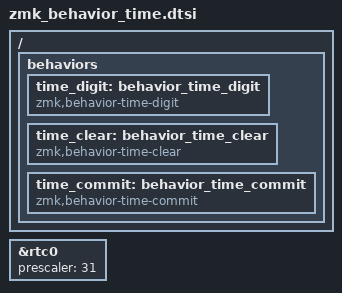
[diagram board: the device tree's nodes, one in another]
/*
 * Copyright (c) 2024 The ZMK Contributors
 *
 * SPDX-License-Identifier: MIT
 */

#include <dt-bindings/zmk/behaviors.h>

/ {
    behaviors {
        time_digit: behavior_time_digit {
            compatible = "zmk,behavior-time-digit";
            #binding-cells = <1>;
        };

        time_clear: behavior_time_clear {
            compatible = "zmk,behavior-time-clear";
            #binding-cells = <0>;
        };

        time_commit: behavior_time_commit {
            compatible = "zmk,behavior-time-commit";
            #binding-cells = <0>;
        };
    };
};

&rtc0 {
    status = "okay";
    prescaler = <31>;    /* 1024 Hz */
};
